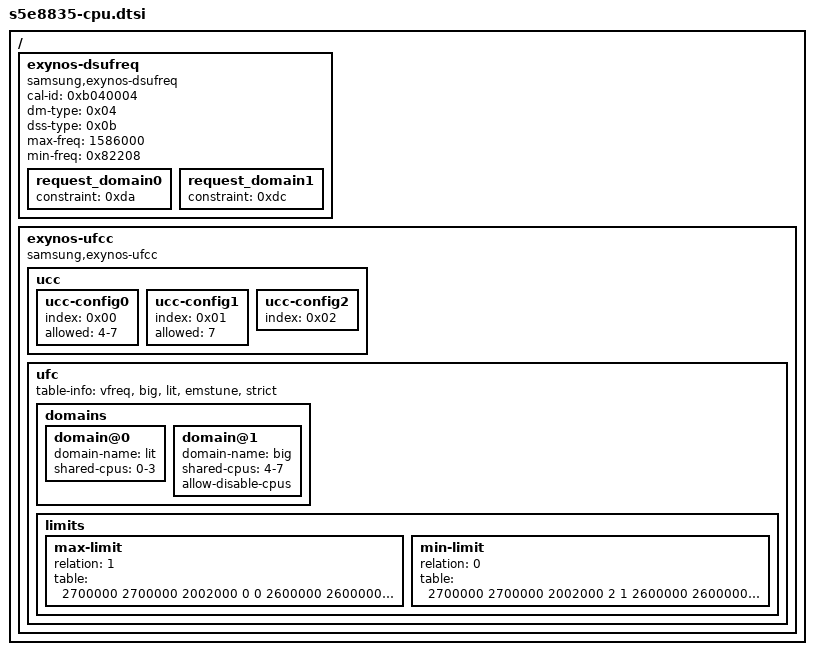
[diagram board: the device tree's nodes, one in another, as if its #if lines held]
#include <linux/kconfig.h>

/{
    exynos-dsufreq {
        compatible = "samsung,exynos-dsufreq";
        status = "okay";
        cal-id = <0xb040004>;
        dm-type = <0x04>;
        dss-type = <0x0b>;
#if IS_ENABLED(CONFIG_SOC_S5E8835_CPU_OC)
        max-freq = <1586000>;
#else
        max-freq = <1352000>;
#endif
        min-freq = <0x82208>;

        request_domain0 {
            device_type = "cpudsu-table";
            constraint = <0xda>;
        };

        request_domain1 {
            device_type = "cpudsu-table";
            constraint = <0xdc>;
        };
    };

	exynos-ufcc {
		compatible = "samsung,exynos-ufcc";
		status = "okay";

		ucc {

			ucc-config0 {
				index = <0x00>;
				allowed = "4-7";
			};

			ucc-config1 {
				index = <0x01>;
				allowed = "7";
			};

			ucc-config2 {
				index = <0x02>;
			};
		};

		ufc {
			table-info = "vfreq", "big", "lit", "emstune", "strict";

			domains {
				domain@0 {
					domain-name = "lit";
					shared-cpus = "0-3";
				};

				domain@1 {
					domain-name = "big";
					shared-cpus = "4-7";
					allow-disable-cpus;
				};
			};

			limits {
				max-limit {
                    relation = <1>;
                    /*       VFREQ   BIG     LIT     EMSTUNE STRICT */
                    table = <
#if IS_ENABLED(CONFIG_SOC_S5E8835_CPU_OC)
                             2700000 2700000 2002000 0       0
                             2600000 2600000 2002000 0       0
                             2496000 2496000 2002000 0       0
#endif
                             2400000 2400000 2002000 0       0
                             2304000 2304000 2002000 0       0
                             2208000 2208000 2002000 0       0
                             2112000 2112000 2002000 0       0
                             2016000 2016000 2002000 0       0
                             1920000 1920000 2002000 0       0
                             1824000 1824000 2002000 0       0
                             1728000 1728000 1920000 0       0
                             1632000 1632000 1824000 0       0
                             1536000 1536000 1824000 0       0
                             1440000 1440000 1728000 0       0
                             1344000 1344000 1632000 0       0
                             1248000 1248000 1632000 0       0
                             1152000 1152000 1632000 0       0
                             1056000 1056000 1632000 0       0
                             960000  960000  1632000 0       0
                             864000  864000  1632000 0       0
                             768000  768000  1632000 0       0
                             672000  672000  1632000 0       0
                             532992  532992  1632000 0       0
                    >;
                };

                min-limit {
                    relation = <0>;
                    /*       VFREQ   BIG     LIT     EMSTUNE STRICT */
                    table = <
#if IS_ENABLED(CONFIG_SOC_S5E8835_CPU_OC)
                             2700000 2700000 2002000 2       1
                             2600000 2600000 2002000 2       1
                             2496000 2496000 2002000 2       1
#endif
                             2400000 2400000 2002000 2       1
                             2304000 2304000 2002000 2       1
                             2208000 2208000 1536000 1       1
                             2112000 2112000 1536000 1       1
                             2016000 2016000 1536000 1       1
                             1920000 1920000 1536000 1       1
                             1824000 1824000 1536000 1       1
                             1728000 1728000 960000  1       1
                             1632000 1632000 960000  1       1
                             1536000 1536000 960000  1       1
                             1440000 1440000 960000  1       1
                             1344000 1344000 960000  1       1
                             1248000 1248000 768000  1       1
                             1152000 1152000 768000  1       1
                             1056000 1056000 768000  1       1
                             960000  960000  768000  0       0
                             864000  864000  768000  0       0
                             768000  768000  768000  0       0
                             672000  672000  768000  0       0
                             532992  532992  768000  0       0
                    >;
                };
			};
		};
	};
};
